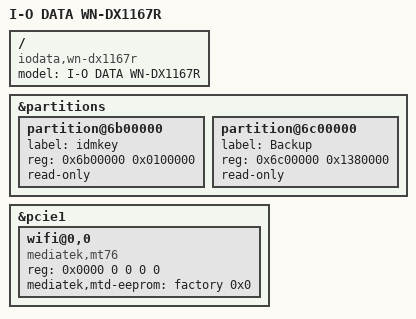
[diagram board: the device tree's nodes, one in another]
// SPDX-License-Identifier: GPL-2.0-or-later OR MIT

#include "mt7621_iodata_wn-xx-xr.dtsi"

/ {
	compatible = "iodata,wn-dx1167r", "mediatek,mt7621-soc";
	model = "I-O DATA WN-DX1167R";
};

&partitions {
	partition@6b00000 {
		label = "idmkey";
		reg = <0x6b00000 0x0100000>;
		read-only;
	};

	partition@6c00000 {
		label = "Backup";
		reg = <0x6c00000 0x1380000>;
		read-only;
	};
};

&pcie1 {
	wifi@0,0 {
		compatible = "mediatek,mt76";
		reg = <0x0000 0 0 0 0>;
		mediatek,mtd-eeprom = <&factory 0x0>;
	};
};
